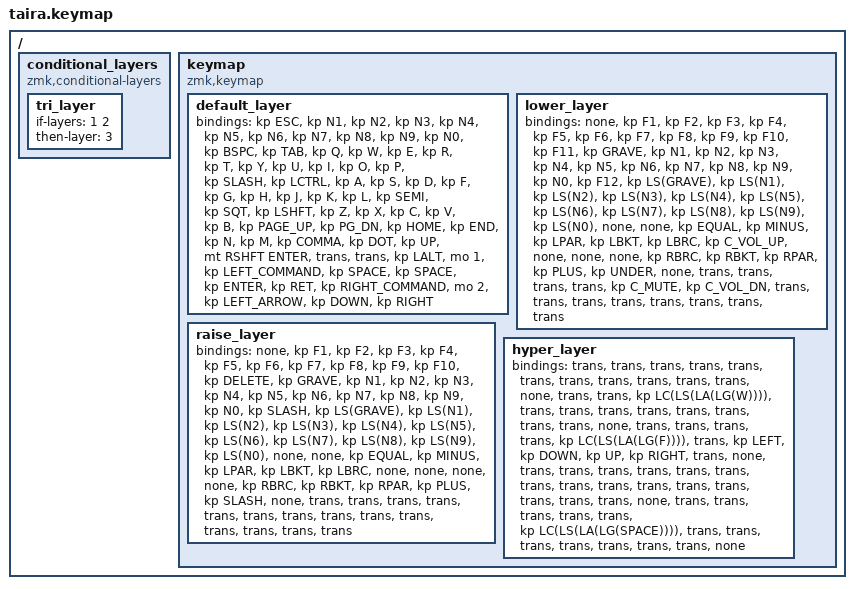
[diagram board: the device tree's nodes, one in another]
/*
 * Copyright (c) 2020 The ZMK Contributors
 *
 * SPDX-License-Identifier: MIT
 */

#include <behaviors.dtsi>
#include <dt-bindings/zmk/keys.h>

#define DEFAULT 0
#define LOWER   1
#define RAISE   2
#define ADJUST  3
#define HYPER   4
#define GAME    5

/ {
    conditional_layers {
        compatible = "zmk,conditional-layers";

        tri_layer {
            if-layers = <1 2>;
            then-layer = <3>;
        };
    };

    keymap {
        compatible = "zmk,keymap";

        default_layer {
            /* QWERTY
 * .----------------------------------------------------------------------------------------------------------------------------------.
 * |  `   |   1  |   2  |   3  |   4  |   5  |                                              |   6  |   7  |   8  |   9  |   0  | PScr |
 * |-------------+------+------+------+------+------+------+-------+-+-------+-------+------+------+------+------+------+------+------|
 * | ESC  |   Q  |   W  |   E  |   R  |   T  |                                              |   Y  |   U  |   I  |   O  |   P  |  \   |
 * |-------------+------+------+------+------+------+------+-------+-+-------+-------+------+------+------+------+------+------+------|
 * | Tab  |   A  |   S  |   D  |   F  |   G  |                                              |   H  |   J  |   K  |   L  |   ;  |  '   |
 * |-------------+------+------+------+------+------+------+-------+-+-------+-------+------+------+------+------+------+------+------|
 * | Shift|   Z  |   X  |   C  |   V  |   B  |      | Del  | PGDN  | | PGUP  | Home  |      |   N  |   M  |   ,  |   .  |   /  | Shift|
 * |-------------+------+------+------+------+------+------+-------+-+-------+-------+------+------+------+------+------+------+------|
 * | Ctrl | Alt  | Meta | Alt  |             | Meta | Space| Lower | | Raise | Enter | RAlt |             | LEFT | DOWN | UP   | RIGHT|
 * .----------------------------------------------------------------------------------------------------------------------------------.
 */

            bindings = <
&kp ESC  &kp N1  &kp N2  &kp N3  &kp N4  &kp N5  &kp N6  &kp N7  &kp N8  &kp N9  &kp N0  &kp BSPC  &kp TAB  &kp Q  &kp W  &kp E  &kp R  &kp T  &kp Y  &kp U  &kp I  &kp O  &kp P  &kp SLASH  &kp LCTRL  &kp A  &kp S  &kp D  &kp F  &kp G  &kp H  &kp J  &kp K  &kp L  &kp SEMI  &kp SQT  &kp LSHFT  &kp Z  &kp X  &kp C  &kp V  &kp B  &kp PAGE_UP  &kp PG_DN  &kp HOME  &kp END  &kp N  &kp M  &kp COMMA  &kp DOT  &kp UP  &mt RSHFT ENTER  &trans  &trans  &kp LALT  &mo 1  &kp LEFT_COMMAND  &kp SPACE  &kp SPACE  &kp ENTER  &kp RET  &kp RIGHT_COMMAND  &mo 2  &kp LEFT_ARROW  &kp DOWN  &kp RIGHT
            >;
        };

        lower_layer {
            /* QWERTY
 * .----------------------------------------------------------------------------------------------------------------------------------.
 * |  `   |   1  |   2  |   3  |   4  |   5  |                                              |   6  |   7  |   8  |   9  |   0  | PScr |
 * |-------------+------+------+------+------+------+------+-------+-+-------+-------+------+------+------+------+------+------+------|
 * | ESC  |   Q  |   W  |   E  |   R  |   T  |                                              |   Y  |   U  |   I  |   O  |   P  |  \   |
 * |-------------+------+------+------+------+------+------+-------+-+-------+-------+------+------+------+------+------+------+------|
 * | Tab  |   A  |   S  |   D  |   F  |   G  |                                              |   H  |   J  |   K  |   L  |   ;  |  '   |
 * |-------------+------+------+------+------+------+------+-------+-+-------+-------+------+------+------+------+------+------+------|
 * | Shift|   Z  |   X  |   C  |   V  |   B  |      | Del  | PGDN  | | PGUP  | Home  |      |   N  |   M  |   ,  |   .  |   /  | Shift|
 * |-------------+------+------+------+------+------+------+-------+-+-------+-------+------+------+------+------+------+------+------|
 * | Ctrl | Alt  | Meta | Alt  |             | Meta | Space| Lower | | Raise | Enter | RAlt |             | LEFT | DOWN | UP   | RIGHT|
 * .----------------------------------------------------------------------------------------------------------------------------------.
 */

            bindings = <
&none  &kp F1  &kp F2  &kp F3  &kp F4  &kp F5  &kp F6  &kp F7  &kp F8  &kp F9  &kp F10  &kp F11  &kp GRAVE  &kp N1  &kp N2  &kp N3  &kp N4  &kp N5  &kp N6  &kp N7  &kp N8  &kp N9  &kp N0  &kp F12  &kp LS(GRAVE)  &kp LS(N1)  &kp LS(N2)  &kp LS(N3)  &kp LS(N4)  &kp LS(N5)  &kp LS(N6)  &kp LS(N7)  &kp LS(N8)  &kp LS(N9)  &kp LS(N0)  &none  &none  &kp EQUAL  &kp MINUS  &kp LPAR  &kp LBKT  &kp LBRC  &kp C_VOL_UP  &none  &none  &none  &kp RBRC  &kp RBKT  &kp RPAR  &kp PLUS  &kp UNDER  &none  &trans  &trans  &trans  &trans  &kp C_MUTE  &kp C_VOL_DN  &trans  &trans  &trans  &trans  &trans  &trans  &trans  &trans
            >;
        };

        raise_layer {
            /* QWERTY
 * .----------------------------------------------------------------------------------------------------------------------------------.
 * |  `   |   1  |   2  |   3  |   4  |   5  |                                              |   6  |   7  |   8  |   9  |   0  | PScr |
 * |-------------+------+------+------+------+------+------+-------+-+-------+-------+------+------+------+------+------+------+------|
 * | ESC  |   Q  |   W  |   E  |   R  |   T  |                                              |   Y  |   U  |   I  |   O  |   P  |  \   |
 * |-------------+------+------+------+------+------+------+-------+-+-------+-------+------+------+------+------+------+------+------|
 * | Tab  |   A  |   S  |   D  |   F  |   G  |                                              |   H  |   J  |   K  |   L  |   ;  |  '   |
 * |-------------+------+------+------+------+------+------+-------+-+-------+-------+------+------+------+------+------+------+------|
 * | Shift|   Z  |   X  |   C  |   V  |   B  |      | Del  | PGDN  | | PGUP  | Home  |      |   N  |   M  |   ,  |   .  |   /  | Shift|
 * |-------------+------+------+------+------+------+------+-------+-+-------+-------+------+------+------+------+------+------+------|
 * | Ctrl | Alt  | Meta | Alt  |             | Meta | Space| Lower | | Raise | Enter | RAlt |             | LEFT | DOWN | UP   | RIGHT|
 * .----------------------------------------------------------------------------------------------------------------------------------.
 */

            bindings = <
&none  &kp F1  &kp F2  &kp F3  &kp F4  &kp F5  &kp F6  &kp F7  &kp F8  &kp F9  &kp F10  &kp DELETE  &kp GRAVE  &kp N1  &kp N2  &kp N3  &kp N4  &kp N5  &kp N6  &kp N7  &kp N8  &kp N9  &kp N0  &kp SLASH  &kp LS(GRAVE)  &kp LS(N1)  &kp LS(N2)  &kp LS(N3)  &kp LS(N4)  &kp LS(N5)  &kp LS(N6)  &kp LS(N7)  &kp LS(N8)  &kp LS(N9)  &kp LS(N0)  &none  &none  &kp EQUAL  &kp MINUS  &kp LPAR  &kp LBKT  &kp LBRC  &none  &none  &none  &none  &kp RBRC  &kp RBKT  &kp RPAR  &kp PLUS  &kp SLASH  &none  &trans  &trans  &trans  &trans  &trans  &trans  &trans  &trans  &trans  &trans  &trans  &trans  &trans  &trans
            >;
        };

        hyper_layer {
            /* QWERTY
 * .----------------------------------------------------------------------------------------------------------------------------------.
 * |  `   |   1  |   2  |   3  |   4  |   5  |                                              |   6  |   7  |   8  |   9  |   0  | PScr |
 * |-------------+------+------+------+------+------+------+-------+-+-------+-------+------+------+------+------+------+------+------|
 * | ESC  |   Q  |   W  |   E  |   R  |   T  |                                              |   Y  |   U  |   I  |   O  |   P  |  \   |
 * |-------------+------+------+------+------+------+------+-------+-+-------+-------+------+------+------+------+------+------+------|
 * | Tab  |   A  |   S  |   D  |   F  |   G  |                                              |   H  |   J  |   K  |   L  |   ;  |  '   |
 * |-------------+------+------+------+------+------+------+-------+-+-------+-------+------+------+------+------+------+------+------|
 * | Shift|   Z  |   X  |   C  |   V  |   B  |      | Del  | PGDN  | | PGUP  | Home  |      |   N  |   M  |   ,  |   .  |   /  | Shift|
 * |-------------+------+------+------+------+------+------+-------+-+-------+-------+------+------+------+------+------+------+------|
 * | Ctrl | Alt  | Meta | Alt  |             | Meta | Space| Lower | | Raise | Enter | RAlt |             | LEFT | DOWN | UP   | RIGHT|
 * .----------------------------------------------------------------------------------------------------------------------------------.
 */

            bindings = <
&trans  &trans  &trans  &trans  &trans  &trans  &trans  &trans  &trans  &trans  &trans  &none  &trans  &trans  &kp LC(LS(LA(LG(W))))  &trans  &trans  &trans  &trans  &trans  &trans  &trans  &trans  &none  &trans  &trans  &trans  &trans  &kp LC(LS(LA(LG(F))))  &trans  &kp LEFT  &kp DOWN  &kp UP  &kp RIGHT  &trans  &none  &trans  &trans  &trans  &trans  &trans  &trans  &trans  &trans  &trans  &trans  &trans  &trans  &trans  &trans  &trans  &none  &trans  &trans  &trans  &trans  &trans  &kp LC(LS(LA(LG(SPACE))))  &trans  &trans  &trans  &trans  &trans  &trans  &trans  &none
            >;
        };
    };
};
